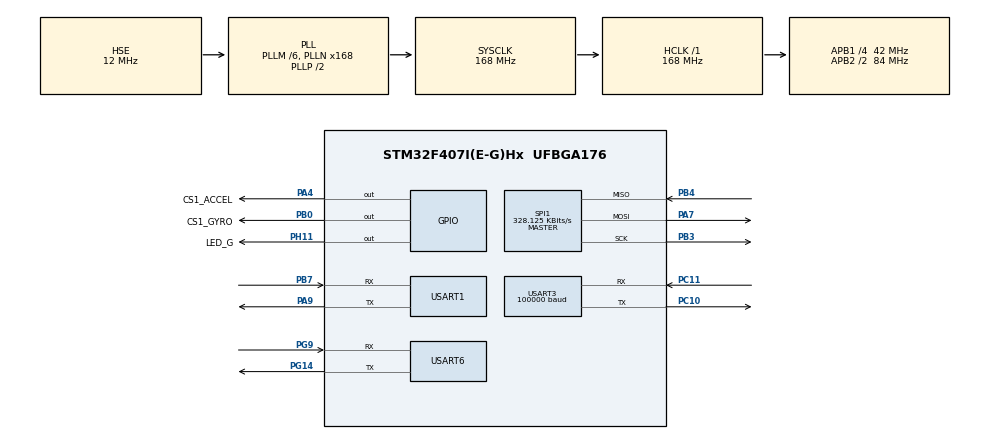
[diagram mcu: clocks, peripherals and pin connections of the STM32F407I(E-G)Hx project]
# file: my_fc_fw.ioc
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Dma.Request0=USART3_RX
Dma.USART3_RX.0.Direction=DMA_PERIPH_TO_MEMORY
Dma.USART3_RX.0.FIFOMode=DMA_FIFOMODE_DISABLE
Dma.USART3_RX.0.Instance=DMA1_Stream1
Dma.USART3_RX.0.MemDataAlignment=DMA_MDATAALIGN_BYTE
Dma.USART3_RX.0.MemInc=DMA_MINC_ENABLE
Dma.USART3_RX.0.Mode=DMA_NORMAL
Dma.USART3_RX.0.PeriphDataAlignment=DMA_PDATAALIGN_BYTE
Dma.USART3_RX.0.PeriphInc=DMA_PINC_DISABLE
Dma.USART3_RX.0.Priority=DMA_PRIORITY_HIGH
FREERTOS.Tasks01=defaultTask,0,128,StartDefaultTask,Default,NULL,Dynamic,NULL,NULL;bmi088process,0,1024,bmi088process_entry,Default,NULL,Dynamic,NULL,NULL;debug_output,-1,1024,debug_output_entry,Default,NULL,Dynamic,NULL,NULL
Mcu.Family=STM32F4
Mcu.Name=STM32F407I(E-G)Hx
Mcu.Package=UFBGA176
NVIC.DMA1_Stream1_IRQn=true\:5\:0\:false\:false\:true\:true\:false\:true\:true
NVIC.PriorityGroup=NVIC_PRIORITYGROUP_4
NVIC.TIM6_DAC_IRQn=true\:15\:0\:false\:false\:true\:false\:false\:true\:true
NVIC.TimeBase=TIM6_DAC_IRQn
NVIC.TimeBaseIP=TIM6
NVIC.USART1_IRQn=true\:5\:0\:false\:false\:true\:true\:true\:true\:true
NVIC.USART3_IRQn=true\:5\:0\:false\:false\:true\:true\:true\:true\:true
PA13.Mode=Serial_Wire
PA13.Signal=SYS_JTMS-SWDIO
PA14.Mode=Serial_Wire
PA14.Signal=SYS_JTCK-SWCLK
PA4.GPIO_Label=CS1_ACCEL
PA4.GPIO_Speed=GPIO_SPEED_FREQ_HIGH
PA4.Signal=GPIO_Output
PA7.Mode=Full_Duplex_Master
PA7.Signal=SPI1_MOSI
PA9.Mode=Asynchronous
PA9.Signal=USART1_TX
PB0.GPIO_Label=CS1_GYRO
PB0.GPIO_Speed=GPIO_SPEED_FREQ_HIGH
PB0.Signal=GPIO_Output
PB3.Mode=Full_Duplex_Master
PB3.Signal=SPI1_SCK
PB4.Mode=Full_Duplex_Master
PB4.Signal=SPI1_MISO
PB7.Mode=Asynchronous
PB7.Signal=USART1_RX
PC10.Mode=Asynchronous
PC10.Signal=USART3_TX
PC11.Mode=Asynchronous
PC11.Signal=USART3_RX
PG14.Mode=Asynchronous
PG14.Signal=USART6_TX
PG9.Mode=Asynchronous
PG9.Signal=USART6_RX
PH0-OSC_IN.Mode=HSE-External-Oscillator
PH0-OSC_IN.Signal=RCC_OSC_IN
PH1-OSC_OUT.Mode=HSE-External-Oscillator
PH1-OSC_OUT.Signal=RCC_OSC_OUT
PH11.GPIO_Label=LED_G
PH11.Signal=GPIO_Output
ProjectManager.HeapSize=0x200
ProjectManager.StackSize=0x400
ProjectManager.TargetToolchain=STM32CubeIDE
RCC.48MHZClocksFreq_Value=84000000
RCC.AHBFreq_Value=168000000
RCC.APB1CLKDivider=RCC_HCLK_DIV4
RCC.APB1Freq_Value=42000000
RCC.APB1TimFreq_Value=84000000
RCC.APB2CLKDivider=RCC_HCLK_DIV2
RCC.APB2Freq_Value=84000000
RCC.APB2TimFreq_Value=168000000
RCC.CortexFreq_Value=168000000
RCC.HCLKFreq_Value=168000000
RCC.HSE_VALUE=12000000
RCC.HSI_VALUE=16000000
RCC.LSE_VALUE=32768
RCC.PLLM=6
RCC.PLLN=168
RCC.PLLSourceVirtual=RCC_PLLSOURCE_HSE
RCC.SYSCLKFreq_VALUE=168000000
RCC.SYSCLKSource=RCC_SYSCLKSOURCE_PLLCLK
RCC.VCOOutputFreq_Value=336000000
SPI1.BaudRatePrescaler=SPI_BAUDRATEPRESCALER_256
SPI1.CLKPhase=SPI_PHASE_2EDGE
SPI1.CLKPolarity=SPI_POLARITY_HIGH
SPI1.CalculateBaudRate=328.125 KBits/s
SPI1.Direction=SPI_DIRECTION_2LINES
SPI1.Mode=SPI_MODE_MASTER
SPI1.VirtualType=VM_MASTER
USART1.VirtualMode=VM_ASYNC
USART3.BaudRate=100000
USART3.Mode=MODE_RX
USART3.Parity=PARITY_EVEN
USART3.StopBits=STOPBITS_1
USART3.VirtualMode=VM_ASYNC
USART3.WordLength=WORDLENGTH_9B
USART6.VirtualMode=VM_ASYNC
VP_FREERTOS_VS_CMSIS_V1.Mode=CMSIS_V1
VP_SYS_VS_tim6.Mode=TIM6
board=custom

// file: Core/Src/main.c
/* USER CODE BEGIN Header */
/**
  ******************************************************************************
  * @file           : main.c
  * @brief          : Main program body
  ******************************************************************************
  * @attention
  *
  * Copyright (c) 2022 STMicroelectronics.
  * All rights reserved.
  *
  * This software is licensed under terms that can be found in the LICENSE file
  * in the root directory of this software component.
  * If no LICENSE file comes with this software, it is provided AS-IS.
  *
  ******************************************************************************
  */
/* USER CODE END Header */
#include "main.h"
#include "cmsis_os.h"

SPI_HandleTypeDef hspi1;

UART_HandleTypeDef huart1;
UART_HandleTypeDef huart3;
UART_HandleTypeDef huart6;
DMA_HandleTypeDef hdma_usart3_rx;

osThreadId defaultTaskHandle;
osThreadId bmi088processHandle;
osThreadId debug_outputHandle;

void SystemClock_Config(void);
static void MX_GPIO_Init(void);
static void MX_DMA_Init(void);
static void MX_SPI1_Init(void);
static void MX_USART1_UART_Init(void);
static void MX_USART6_UART_Init(void);
static void MX_USART3_UART_Init(void);
void StartDefaultTask(void const * argument);
void bmi088process_entry(void const * argument);
void debug_output_entry(void const * argument);

int main(void)
{

  /* MCU Configuration--------------------------------------------------------*/

  /* Reset of all peripherals, Initializes the Flash interface and the Systick. */
  HAL_Init();

  /* Configure the system clock */
  SystemClock_Config();

  /* Initialize all configured peripherals */
  MX_GPIO_Init();
  MX_DMA_Init();
  MX_SPI1_Init();
  MX_USART1_UART_Init();
  MX_USART6_UART_Init();
  MX_USART3_UART_Init();

  /* Create the thread(s) */
  /* definition and creation of defaultTask */
  osThreadDef(defaultTask, StartDefaultTask, osPriorityNormal, 0, 128);
  defaultTaskHandle = osThreadCreate(osThread(defaultTask), NULL);

  /* definition and creation of bmi088process */
  osThreadDef(bmi088process, bmi088process_entry, osPriorityNormal, 0, 1024);
  bmi088processHandle = osThreadCreate(osThread(bmi088process), NULL);

  /* definition and creation of debug_output */
  osThreadDef(debug_output, debug_output_entry, osPriorityBelowNormal, 0, 1024);
  debug_outputHandle = osThreadCreate(osThread(debug_output), NULL);

  /* Start scheduler */
  osKernelStart();

  /* We should never get here as control is now taken by the scheduler */
  /* Infinite loop */
  while (1)
  {

  }
}

void SystemClock_Config(void)
{
  RCC_OscInitTypeDef RCC_OscInitStruct = {0};
  RCC_ClkInitTypeDef RCC_ClkInitStruct = {0};

  /** Configure the main internal regulator output voltage
  */
  __HAL_RCC_PWR_CLK_ENABLE();
  __HAL_PWR_VOLTAGESCALING_CONFIG(PWR_REGULATOR_VOLTAGE_SCALE1);

  /** Initializes the RCC Oscillators according to the specified parameters
  * in the RCC_OscInitTypeDef structure.
  */
  RCC_OscInitStruct.OscillatorType = RCC_OSCILLATORTYPE_HSE;
  RCC_OscInitStruct.HSEState = RCC_HSE_ON;
  RCC_OscInitStruct.PLL.PLLState = RCC_PLL_ON;
  RCC_OscInitStruct.PLL.PLLSource = RCC_PLLSOURCE_HSE;
  RCC_OscInitStruct.PLL.PLLM = 6;
  RCC_OscInitStruct.PLL.PLLN = 168;
  RCC_OscInitStruct.PLL.PLLP = RCC_PLLP_DIV2;
  RCC_OscInitStruct.PLL.PLLQ = 4;
  if (HAL_RCC_OscConfig(&RCC_OscInitStruct) != HAL_OK)
  {
    Error_Handler();
  }

  /** Initializes the CPU, AHB and APB buses clocks
  */
  RCC_ClkInitStruct.ClockType = RCC_CLOCKTYPE_HCLK|RCC_CLOCKTYPE_SYSCLK
                              |RCC_CLOCKTYPE_PCLK1|RCC_CLOCKTYPE_PCLK2;
  RCC_ClkInitStruct.SYSCLKSource = RCC_SYSCLKSOURCE_PLLCLK;
  RCC_ClkInitStruct.AHBCLKDivider = RCC_SYSCLK_DIV1;
  RCC_ClkInitStruct.APB1CLKDivider = RCC_HCLK_DIV4;
  RCC_ClkInitStruct.APB2CLKDivider = RCC_HCLK_DIV2;

  if (HAL_RCC_ClockConfig(&RCC_ClkInitStruct, FLASH_LATENCY_5) != HAL_OK)
  {
    Error_Handler();
  }
}

static void MX_SPI1_Init(void)
{

  /* SPI1 parameter configuration*/
  hspi1.Instance = SPI1;
  hspi1.Init.Mode = SPI_MODE_MASTER;
  hspi1.Init.Direction = SPI_DIRECTION_2LINES;
  hspi1.Init.DataSize = SPI_DATASIZE_8BIT;
  hspi1.Init.CLKPolarity = SPI_POLARITY_HIGH;
  hspi1.Init.CLKPhase = SPI_PHASE_2EDGE;
  hspi1.Init.NSS = SPI_NSS_SOFT;
  hspi1.Init.BaudRatePrescaler = SPI_BAUDRATEPRESCALER_256;
  hspi1.Init.FirstBit = SPI_FIRSTBIT_MSB;
  hspi1.Init.TIMode = SPI_TIMODE_DISABLE;
  hspi1.Init.CRCCalculation = SPI_CRCCALCULATION_DISABLE;
  hspi1.Init.CRCPolynomial = 10;
  if (HAL_SPI_Init(&hspi1) != HAL_OK)
  {
    Error_Handler();
  }

}

static void MX_USART1_UART_Init(void)
{

  huart1.Instance = USART1;
  huart1.Init.BaudRate = 115200;
  huart1.Init.WordLength = UART_WORDLENGTH_8B;
  huart1.Init.StopBits = UART_STOPBITS_1;
  huart1.Init.Parity = UART_PARITY_NONE;
  huart1.Init.Mode = UART_MODE_TX_RX;
  huart1.Init.HwFlowCtl = UART_HWCONTROL_NONE;
  huart1.Init.OverSampling = UART_OVERSAMPLING_16;
  if (HAL_UART_Init(&huart1) != HAL_OK)
  {
    Error_Handler();
  }

}

static void MX_USART3_UART_Init(void)
{

  huart3.Instance = USART3;
  huart3.Init.BaudRate = 100000;
  huart3.Init.WordLength = UART_WORDLENGTH_8B;
  huart3.Init.StopBits = UART_STOPBITS_2;
  huart3.Init.Parity = UART_PARITY_EVEN;
  huart3.Init.Mode = UART_MODE_RX;
  huart3.Init.HwFlowCtl = UART_HWCONTROL_NONE;
  huart3.Init.OverSampling = UART_OVERSAMPLING_16;
  if (HAL_UART_Init(&huart3) != HAL_OK)
  {
    Error_Handler();
  }

}

static void MX_USART6_UART_Init(void)
{

  huart6.Instance = USART6;
  huart6.Init.BaudRate = 115200;
  huart6.Init.WordLength = UART_WORDLENGTH_8B;
  huart6.Init.StopBits = UART_STOPBITS_1;
  huart6.Init.Parity = UART_PARITY_NONE;
  huart6.Init.Mode = UART_MODE_TX_RX;
  huart6.Init.HwFlowCtl = UART_HWCONTROL_NONE;
  huart6.Init.OverSampling = UART_OVERSAMPLING_16;
  if (HAL_UART_Init(&huart6) != HAL_OK)
  {
    Error_Handler();
  }

}

static void MX_DMA_Init(void)
{

  /* DMA controller clock enable */
  __HAL_RCC_DMA1_CLK_ENABLE();

  /* DMA interrupt init */
  /* DMA1_Stream1_IRQn interrupt configuration */
  HAL_NVIC_SetPriority(DMA1_Stream1_IRQn, 5, 0);
  HAL_NVIC_EnableIRQ(DMA1_Stream1_IRQn);

}

static void MX_GPIO_Init(void)
{
  GPIO_InitTypeDef GPIO_InitStruct = {0};

  /* GPIO Ports Clock Enable */
  __HAL_RCC_GPIOG_CLK_ENABLE();
  __HAL_RCC_GPIOB_CLK_ENABLE();
  __HAL_RCC_GPIOA_CLK_ENABLE();
  __HAL_RCC_GPIOC_CLK_ENABLE();
  __HAL_RCC_GPIOH_CLK_ENABLE();

  /*Configure GPIO pin Output Level */
  HAL_GPIO_WritePin(LED_G_GPIO_Port, LED_G_Pin, GPIO_PIN_RESET);

  /*Configure GPIO pin Output Level */
  HAL_GPIO_WritePin(CS1_ACCEL_GPIO_Port, CS1_ACCEL_Pin, GPIO_PIN_RESET);

  /*Configure GPIO pin Output Level */
  HAL_GPIO_WritePin(CS1_GYRO_GPIO_Port, CS1_GYRO_Pin, GPIO_PIN_RESET);

  /*Configure GPIO pin : LED_G_Pin */
  GPIO_InitStruct.Pin = LED_G_Pin;
  GPIO_InitStruct.Mode = GPIO_MODE_OUTPUT_PP;
  GPIO_InitStruct.Pull = GPIO_NOPULL;
  GPIO_InitStruct.Speed = GPIO_SPEED_FREQ_LOW;
  HAL_GPIO_Init(LED_G_GPIO_Port, &GPIO_InitStruct);

  /*Configure GPIO pin : CS1_ACCEL_Pin */
  GPIO_InitStruct.Pin = CS1_ACCEL_Pin;
  GPIO_InitStruct.Mode = GPIO_MODE_OUTPUT_PP;
  GPIO_InitStruct.Pull = GPIO_NOPULL;
  GPIO_InitStruct.Speed = GPIO_SPEED_FREQ_HIGH;
  HAL_GPIO_Init(CS1_ACCEL_GPIO_Port, &GPIO_InitStruct);

  /*Configure GPIO pin : CS1_GYRO_Pin */
  GPIO_InitStruct.Pin = CS1_GYRO_Pin;
  GPIO_InitStruct.Mode = GPIO_MODE_OUTPUT_PP;
  GPIO_InitStruct.Pull = GPIO_NOPULL;
  GPIO_InitStruct.Speed = GPIO_SPEED_FREQ_HIGH;
  HAL_GPIO_Init(CS1_GYRO_GPIO_Port, &GPIO_InitStruct);

}

void StartDefaultTask(void const * argument)
{
  for(;;)
  {
    osDelay(1);
  }
}

__weak void bmi088process_entry(void const * argument)
{
  /* USER CODE BEGIN bmi088process_entry */
  /* Infinite loop */
  for(;;)
  {
	  //non loop
	  osDelay(100);
  }
  /* USER CODE END bmi088process_entry */
}

__weak void debug_output_entry(void const * argument)
{
  for(;;)
  {
    osDelay(1);
  }
}

void HAL_TIM_PeriodElapsedCallback(TIM_HandleTypeDef *htim)
{
  if (htim->Instance == TIM6) {
    HAL_IncTick();
  }
}

void Error_Handler(void)
{
  __disable_irq();
  while (1)
  {
  }
}
